# STM32H743 register map
File version: 2.4
CPU: CM7 r0p1, little endian, MPU, FPU, 4 interrupt priority bits
Registers are 32-bit, read-write, reset 0x0 unless marked. A register's access mark holds for its fields unless they carry their own. Offsets are from the block's base; [hi:lo] are bit positions; {n}, {i} and the like mark numbered series; 'fields as' and 'values as' point back to an identical list.

## BDMA — BDMA（基本 DMA 控制器）
Base 0x58025400
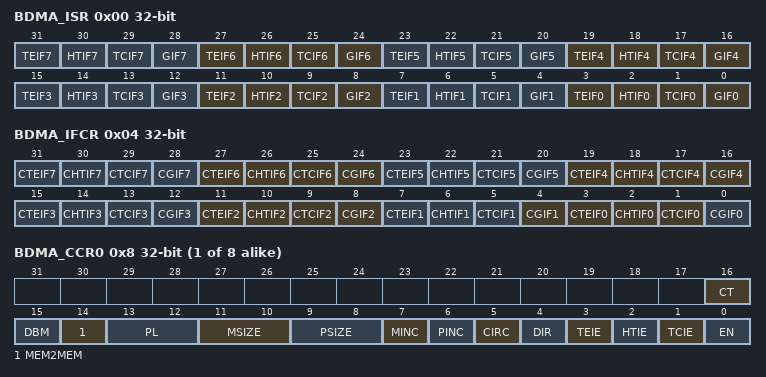
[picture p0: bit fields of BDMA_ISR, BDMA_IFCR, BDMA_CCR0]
0x00 BDMA_ISR ro — BDMA 中断状态寄存器
  [4n+3] TEIF{n} (n=0..7) — 通道 {n} 传输错误（TE）标志
    0=未发生 TE 事件; 1=发生了 TE 事件
  [4n+2] HTIF{n} (n=0..7) — 通道 {n} 半传输（HT）标志
    0=未发生 HT 事件; 1=发生了 HT 事件
  [4n+1] TCIF{n} (n=0..7) — 通道 {n} 传输完成（TC）标志
    0=未发生 TC 事件; 1=发生了 TC 事件
  [4n] GIF{n} (n=0..7) — 通道 {n} 全局中断标志
    0=未发生 TE、HT 或 TC 事件; 1=发生了 TE、HT 或 TC 事件
0x04 BDMA_IFCR wo — BDMA 中断标志清零寄存器
  [4n+3] CTEIF{n} (n=0..7) — 通道 {n} 传输错误标志清零
  [4n+2] CHTIF{n} (n=0..7) — 通道 {n} 半传输标志清零
  [4n+1] CTCIF{n} (n=0..7) — 通道 {n} 传输完成标志清零
  [4n] CGIF{n} (n=2..7) — 通道 {n} 全局中断标志清零
  [4] CGIF1 — 通道 0 全局中断标志清零
  [0] CGIF0 — 通道 0 全局中断标志清零
{0x8+0x14*i} BDMA_CCR{i} (i=0..7) — BDMA 通道 {i} 配置寄存器
  [16] CT — 双缓冲模式下 DMA 传输的当前目标存储器。在双缓冲模式下，硬件会在每次通道传输结束时翻转此位。注意：此位由软件置位和清零。通道使能（EN = 1）时不得写入此位。通道使能（EN = 1）时此位为只读。
    0=存储器 0（由 BDMA_CM0AR 指针寻址）; 1=存储器 1（由 BDMA_CM1AR 指针寻址）
  [15] DBM — 双缓冲模式。此位仅在存储器到外设和外设到存储器传输（MEM2MEM=0）时才应置位。处于双缓冲模式时 CIRC 位也必须置位。注意：此位由软件置位和清零。通道使能（EN = 1）时不得写入此位。通道使能（EN = 1）时此位并非只读。
    0=禁止（BDMA 传输结束时存储器地址不切换）; 1=使能（BDMA 传输结束时存储器地址切换）
  [14] MEM2MEM — 存储器到存储器模式。注意：此位由软件置位和清零。通道使能（EN = 1）时不得写入此位。通道使能（EN = 1）时此位为只读。
    0=禁止; 1=使能
  [13:12] PL — 优先级。注意：此字段由软件置位和清零。通道使能（EN = 1）时不得写入此字段。通道使能（EN = 1）时此字段为只读。
    0=低; 1=中; 2=高; 3=极高
  [11:10] MSIZE — 存储器数据宽度。定义每次 DMA 传输到指定存储器的数据宽度。在存储器到存储器模式下，若 DIR = 1 则此字段标识存储器源端，若 DIR = 0 则标识存储器目标端。在外设到外设模式下，若 DIR = 1 则此字段标识外设源端，若 DIR = 0 则标识外设目标端。注意：此字段由软件置位和清零。通道使能（EN = 1）时不得写入此字段。通道使能（EN = 1）时此字段为只读。
    0=8 位; 1=16 位; 2=32 位
  [9:8] PSIZE — 外设数据宽度。定义每次 DMA 传输到指定外设的数据宽度。在存储器到存储器模式下，若 DIR = 1 则此字段标识存储器目标端，若 DIR = 0 则标识存储器源端。在外设到外设模式下，若 DIR = 1 则此字段标识外设目标端，若 DIR = 0 则标识外设源端。注意：此字段由软件置位和清零。通道使能（EN = 1）时不得写入此字段。通道使能（EN = 1）时此字段为只读。
    0=8 位; 1=16 位; 2=32 位
  [7] MINC — 存储器地址递增模式。定义每次 DMA 传输到指定存储器时的地址递增方式。在存储器到存储器模式下，若 DIR = 1 则此字段标识存储器源地址，若 DIR = 0 则标识存储器目标地址。在外设到外设模式下，若 DIR = 1 则此字段标识外设源地址，若 DIR = 0 则标识外设目标地址。注意：此位由软件置位和清零。通道使能（EN = 1）时不得写入此位。通道使能（EN = 1）时此位为只读。
    0=禁止; 1=使能
  [6] PINC — 外设地址递增模式。定义每次 DMA 传输到指定外设时的地址递增方式。在存储器到存储器模式下，若 DIR = 1 则此字段标识存储器目标地址，若 DIR = 0 则标识存储器源地址。在外设到外设模式下，若 DIR = 1 则此字段标识外设目标地址，若 DIR = 0 则标识外设源地址。注意：此位由软件置位和清零。通道使能（EN = 1）时不得写入此位。通道使能（EN = 1）时此位为只读。
    0=禁止; 1=使能
  [5] CIRC — 循环模式。注意：此位由软件置位和清零。通道使能（EN = 1）时不得写入此位。通道使能（EN = 1）时此位并非只读。
    0=禁止; 1=使能
  [4] DIR — 数据传输方向。此位仅在存储器到外设和外设到存储器模式下才应置位。源端属性由 PSIZE 和 PINC 以及 BDMA_CPARx 寄存器定义，这在存储器到存储器模式下同样有效。目标端属性由 MSIZE 和 MINC 以及 BDMA_CM0/1ARx 寄存器定义，这在外设到外设模式下同样有效。目标端属性由 PSIZE 和 PINC 以及 BDMA_CPARx 寄存器定义，这在存储器到存储器模式下同样有效。源端属性由 MSIZE 和 MINC 以及 BDMA_CM0/1ARx 寄存器定义，这在外设到外设模式下同样有效。注意：此位由软件置位和清零。通道使能（EN = 1）时不得写入此位。通道使能（EN = 1）时此位为只读。
    0=从外设读取; 1=从存储器读取
  [3] TEIE — 传输错误中断使能。注意：此位由软件置位和清零。通道使能（EN = 1）时不得写入此位。通道使能（EN = 1）时此位并非只读。
    0=禁止; 1=使能
  [2] HTIE — 半传输中断使能。注意：此位由软件置位和清零。通道使能（EN = 1）时不得写入此位。通道使能（EN = 1）时此位并非只读。
    0=禁止; 1=使能
  [1] TCIE — 传输完成中断使能。注意：此位由软件置位和清零。通道使能（EN = 1）时不得写入此位。通道使能（EN = 1）时此位并非只读。
    0=禁止; 1=使能
  [0] EN — 通道使能。当通道发生传输错误时，硬件会清零此位。在 BDMA_ISR 寄存器的 TEIFx 位被清零（通过置位 BDMA_IFCR 寄存器的 CTEIFx 位）之前，软件无法再次置位此位（即重新激活通道 x）。注意：此位由软件置位和清零。
    0=禁止; 1=使能
{0xC+0x14*i} BDMA_CNDTR{i} (i=0..7)
  [15:0] NDT — 待传输的数据量（0 到 2^16 - 1）。通道使能后，硬件会更新此字段：每次 BDMA 执行完一次“先读后写”的传输后该值递减，表示剩余待传输的数据项数量。若通道未处于循环模式（BDMA_CCRx 寄存器中 CIRC = 0），当编程设定的传输数据量完成后，此字段保持为 0。若通道处于循环模式（CIRC = 1），传输完成后会自动重新加载为之前编程设定的值。若此字段为 0，无论通道处于何种状态（使能与否），都不会执行任何传输。注意：此字段由软件置位和清零。通道使能（EN = 1）时不得写入此字段。通道使能（EN = 1）时此字段为只读。
{0x10+0x14*i} BDMA_CPAR{i} (i=0..7)
  [31:0] PA — 外设地址。存放外设数据寄存器的基地址，数据即从该地址读出或写入。当 PSIZE[1:0] = 01（16 位）时，PA[31:0] 的位 0 被忽略，访问自动对齐到半字地址。当 PSIZE = 10（32 位）时，PA[31:0] 的位 1 和位 0 被忽略，访问自动对齐到字地址。在存储器到存储器模式下，若 DIR = 1 则此寄存器标识存储器目标地址，若 DIR = 0 则标识存储器源地址。在外设到外设模式下，若 DIR = 1 则此寄存器标识外设目标地址，若 DIR = 0 则标识外设源地址。注意：此寄存器由软件置位和清零。通道使能（EN = 1）时不得写入此寄存器。通道使能（EN = 1）时此寄存器并非只读。
{0x14+0x14*i} BDMA_CM0AR{i} (i=0..7)
  [31:0] MA — 存储器地址。存放存储器的基地址，数据即从该地址读出或写入。当 MSIZE[1:0] = 01（16 位）时，MA[31:0] 的位 0 被忽略，访问自动对齐到半字地址。当 MSIZE = 10（32 位）时，MA[31:0] 的位 1 和位 0 被忽略，访问自动对齐到字地址。在存储器到存储器模式下，若 DIR = 1 则此寄存器标识存储器源地址，若 DIR = 0 则标识存储器目标地址。在外设到外设模式下，若 DIR = 1 则此寄存器标识外设源地址，若 DIR = 0 则标识外设目标地址。注意：此寄存器由软件置位和清零。通道使能（EN = 1）时不得写入此寄存器。通道使能（EN = 1）时此寄存器并非只读。
{0x18+0x14*i} BDMA_CM1AR{i} (i=0..7)
  fields as BDMA_CM0AR0
